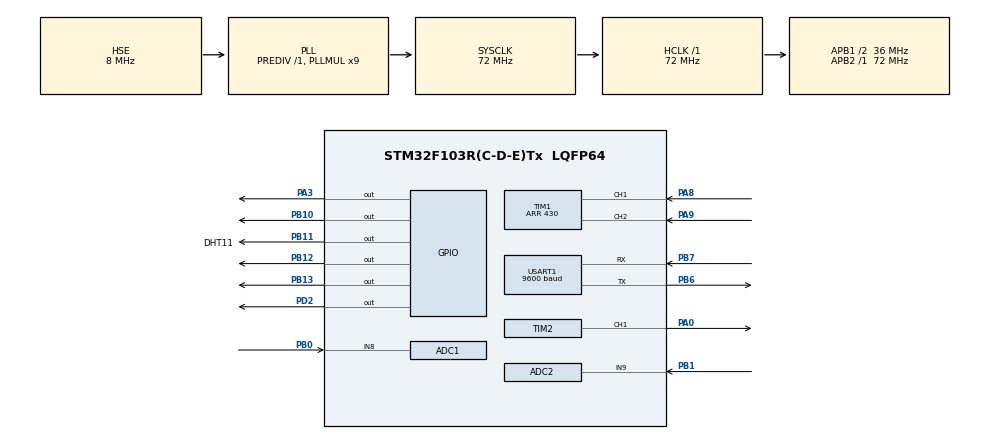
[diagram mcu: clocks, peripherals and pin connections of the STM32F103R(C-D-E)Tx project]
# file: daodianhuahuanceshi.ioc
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ADC1.Channel-18\#ChannelRegularConversion=ADC_CHANNEL_8
ADC1.ContinuousConvMode=DISABLE
ADC1.DataAlign=ADC_DATAALIGN_RIGHT
ADC1.DiscontinuousConvMode=DISABLE
ADC1.EnableAnalogWatchDog=false
ADC1.EnableRegularConversion=ENABLE
ADC1.ExternalTrigConv=ADC_SOFTWARE_START
ADC1.InjNumberOfConversion=0
ADC1.NbrOfConversion=1
ADC1.NbrOfConversionFlag=1
ADC1.Rank-18\#ChannelRegularConversion=1
ADC1.SamplingTime-18\#ChannelRegularConversion=ADC_SAMPLETIME_1CYCLE_5
ADC1.ScanConvMode=ADC_SCAN_DISABLE
ADC1.master=1
ADC2.Channel-2\#ChannelRegularConversion=ADC_CHANNEL_9
ADC2.NbrOfConversionFlag=1
ADC2.Rank-2\#ChannelRegularConversion=1
ADC2.SamplingTime-2\#ChannelRegularConversion=ADC_SAMPLETIME_1CYCLE_5
Mcu.Family=STM32F1
Mcu.Name=STM32F103R(C-D-E)Tx
Mcu.Package=LQFP64
NVIC.PriorityGroup=NVIC_PRIORITYGROUP_4
NVIC.TIM3_IRQn=true\:0\:0\:false\:false\:true\:true
PA0-WKUP.Signal=S_TIM2_CH1_ETR
PA13.Mode=Serial_Wire
PA13.Signal=SYS_JTMS-SWDIO
PA14.Mode=Serial_Wire
PA14.Signal=SYS_JTCK-SWCLK
PA3.GPIO_PuPd=GPIO_PULLUP
PA3.PinState=GPIO_PIN_SET
PA3.Signal=GPIO_Output
PA8.GPIO_PuPd=GPIO_PULLUP
PA8.Signal=S_TIM1_CH1
PA9.GPIO_PuPd=GPIO_PULLUP
PA9.Signal=S_TIM1_CH2
PB0.Signal=ADCx_IN8
PB1.Signal=ADCx_IN9
PB10.PinState=GPIO_PIN_RESET
PB10.Signal=GPIO_Output
PB11.GPIO_Label=DHT11
PB11.GPIO_Speed=GPIO_SPEED_FREQ_HIGH
PB11.PinState=GPIO_PIN_SET
PB11.Signal=GPIO_Output
PB12.Signal=GPIO_Output
PB13.Signal=GPIO_Output
PB6.Mode=Asynchronous
PB6.Signal=USART1_TX
PB7.Mode=Asynchronous
PB7.Signal=USART1_RX
PD0-OSC_IN.Mode=HSE-External-Oscillator
PD0-OSC_IN.Signal=RCC_OSC_IN
PD1-OSC_OUT.Mode=HSE-External-Oscillator
PD1-OSC_OUT.Signal=RCC_OSC_OUT
PD2.Signal=GPIO_Output
ProjectManager.HeapSize=0x200
ProjectManager.StackSize=0x400
ProjectManager.TargetToolchain=MDK-ARM V5
RCC.ADCPresc=RCC_ADCPCLK2_DIV6
RCC.AHBFreq_Value=72000000
RCC.APB1CLKDivider=RCC_HCLK_DIV2
RCC.APB1Freq_Value=36000000
RCC.APB1TimFreq_Value=72000000
RCC.APB2Freq_Value=72000000
RCC.APB2TimFreq_Value=72000000
RCC.HCLKFreq_Value=72000000
RCC.PLLMUL=RCC_PLL_MUL9
RCC.PLLSourceVirtual=RCC_PLLSOURCE_HSE
RCC.SYSCLKFreq_VALUE=72000000
RCC.SYSCLKSource=RCC_SYSCLKSOURCE_PLLCLK
RCC.USBFreq_Value=72000000
SH.ADCx_IN8.0=ADC1_IN8,IN8
SH.ADCx_IN9.0=ADC2_IN9,IN9
SH.S_TIM1_CH1.0=TIM1_CH1,Encoder_Interface
SH.S_TIM1_CH2.0=TIM1_CH2,Encoder_Interface
SH.S_TIM2_CH1_ETR.0=TIM2_CH1,PWM Generation1 CH1
TIM1.EncoderMode=TIM_ENCODERMODE_TI12
TIM1.IC1Prescaler=TIM_ICPSC_DIV1
TIM1.IC2Prescaler=TIM_ICPSC_DIV1
TIM1.Period=430
TIM2.Channel-PWM\ Generation1\ CH1=TIM_CHANNEL_1
TIM2.Period=9999
TIM2.Prescaler=143
TIM2.Pulse-PWM\ Generation1\ CH1=3000
TIM3.Period=999
TIM3.Prescaler=719
USART1.BaudRate=9600
USART1.VirtualMode=VM_ASYNC
VP_TIM2_VS_ClockSourceINT.Mode=Internal
VP_TIM3_VS_ClockSourceINT.Mode=Internal
board=custom

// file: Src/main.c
/**
  ******************************************************************************
  * @file           : main.c
  * @brief          : Main program body
  ******************************************************************************
  ** This notice applies to any and all portions of this file
  * that are not between comment pairs USER CODE BEGIN and
  * USER CODE END. Other portions of this file, whether
  * inserted by the user or by software development tools
  * are owned by their respective copyright owners.
  *
  * COPYRIGHT(c) 2019 STMicroelectronics
  *
  * Redistribution and use in source and binary forms, with or without modification,
  * are permitted provided that the following conditions are met:
  *   1. Redistributions of source code must retain the above copyright notice,
  *      this list of conditions and the following disclaimer.
  *   2. Redistributions in binary form must reproduce the above copyright notice,
  *      this list of conditions and the following disclaimer in the documentation
  *      and/or other materials provided with the distribution.
  *   3. Neither the name of STMicroelectronics nor the names of its contributors
  *      may be used to endorse or promote products derived from this software
  *      without specific prior written permission.
  *
  * THIS SOFTWARE IS PROVIDED BY THE COPYRIGHT HOLDERS AND CONTRIBUTORS "AS IS"
  * AND ANY EXPRESS OR IMPLIED WARRANTIES, INCLUDING, BUT NOT LIMITED TO, THE
  * IMPLIED WARRANTIES OF MERCHANTABILITY AND FITNESS FOR A PARTICULAR PURPOSE ARE
  * DISCLAIMED. IN NO EVENT SHALL THE COPYRIGHT HOLDER OR CONTRIBUTORS BE LIABLE
  * FOR ANY DIRECT, INDIRECT, INCIDENTAL, SPECIAL, EXEMPLARY, OR CONSEQUENTIAL
  * DAMAGES (INCLUDING, BUT NOT LIMITED TO, PROCUREMENT OF SUBSTITUTE GOODS OR
  * SERVICES; LOSS OF USE, DATA, OR PROFITS; OR BUSINESS INTERRUPTION) HOWEVER
  * CAUSED AND ON ANY THEORY OF LIABILITY, WHETHER IN CONTRACT, STRICT LIABILITY,
  * OR TORT (INCLUDING NEGLIGENCE OR OTHERWISE) ARISING IN ANY WAY OUT OF THE USE
  * OF THIS SOFTWARE, EVEN IF ADVISED OF THE POSSIBILITY OF SUCH DAMAGE.
  *
  ******************************************************************************
  */
#include "main.h"
#include "stm32f1xx_hal.h"

/* USER CODE BEGIN Includes */
#include "User.h"
/* USER CODE END Includes */

ADC_HandleTypeDef hadc1;
ADC_HandleTypeDef hadc2;

TIM_HandleTypeDef htim1;
TIM_HandleTypeDef htim2;
TIM_HandleTypeDef htim3;

UART_HandleTypeDef huart1;

/* USER CODE BEGIN PV */
/* Private variables ---------------------------------------------------------*/

/* USER CODE END PV */

void SystemClock_Config(void);
static void MX_GPIO_Init(void);
static void MX_USART1_UART_Init(void);
static void MX_ADC1_Init(void);
static void MX_ADC2_Init(void);
static void MX_TIM1_Init(void);
static void MX_TIM2_Init(void);
static void MX_TIM3_Init(void);

void HAL_TIM_MspPostInit(TIM_HandleTypeDef *htim);

/* USER CODE BEGIN PFP */
/* Private function prototypes -----------------------------------------------*/

/* USER CODE END PFP */

int main(void)
{

  /* MCU Configuration----------------------------------------------------------*/

  /* Reset of all peripherals, Initializes the Flash interface and the Systick. */
  HAL_Init();

  /* Configure the system clock */
  SystemClock_Config();

  /* Initialize all configured peripherals */
  MX_GPIO_Init();
  MX_USART1_UART_Init();
  MX_ADC1_Init();
  MX_ADC2_Init();
  MX_TIM1_Init();
  MX_TIM2_Init();
  MX_TIM3_Init();
  /* USER CODE BEGIN 2 */
    UserInitCallBack();
  /* USER CODE END 2 */

  /* Infinite loop */
  while (1)
  {

  /* USER CODE BEGIN 3 */
      UserServiceCallBack();

  }
  /* USER CODE END 3 */

}

void SystemClock_Config(void)
{

  RCC_OscInitTypeDef RCC_OscInitStruct;
  RCC_ClkInitTypeDef RCC_ClkInitStruct;
  RCC_PeriphCLKInitTypeDef PeriphClkInit;

    /**Initializes the CPU, AHB and APB busses clocks
    */
  RCC_OscInitStruct.OscillatorType = RCC_OSCILLATORTYPE_HSE;
  RCC_OscInitStruct.HSEState = RCC_HSE_ON;
  RCC_OscInitStruct.HSEPredivValue = RCC_HSE_PREDIV_DIV1;
  RCC_OscInitStruct.HSIState = RCC_HSI_ON;
  RCC_OscInitStruct.PLL.PLLState = RCC_PLL_ON;
  RCC_OscInitStruct.PLL.PLLSource = RCC_PLLSOURCE_HSE;
  RCC_OscInitStruct.PLL.PLLMUL = RCC_PLL_MUL9;
  if (HAL_RCC_OscConfig(&RCC_OscInitStruct) != HAL_OK)
  {
    _Error_Handler(__FILE__, __LINE__);
  }

    /**Initializes the CPU, AHB and APB busses clocks
    */
  RCC_ClkInitStruct.ClockType = RCC_CLOCKTYPE_HCLK|RCC_CLOCKTYPE_SYSCLK
                              |RCC_CLOCKTYPE_PCLK1|RCC_CLOCKTYPE_PCLK2;
  RCC_ClkInitStruct.SYSCLKSource = RCC_SYSCLKSOURCE_PLLCLK;
  RCC_ClkInitStruct.AHBCLKDivider = RCC_SYSCLK_DIV1;
  RCC_ClkInitStruct.APB1CLKDivider = RCC_HCLK_DIV2;
  RCC_ClkInitStruct.APB2CLKDivider = RCC_HCLK_DIV1;

  if (HAL_RCC_ClockConfig(&RCC_ClkInitStruct, FLASH_LATENCY_2) != HAL_OK)
  {
    _Error_Handler(__FILE__, __LINE__);
  }

  PeriphClkInit.PeriphClockSelection = RCC_PERIPHCLK_ADC;
  PeriphClkInit.AdcClockSelection = RCC_ADCPCLK2_DIV6;
  if (HAL_RCCEx_PeriphCLKConfig(&PeriphClkInit) != HAL_OK)
  {
    _Error_Handler(__FILE__, __LINE__);
  }

    /**Configure the Systick interrupt time
    */
  HAL_SYSTICK_Config(HAL_RCC_GetHCLKFreq()/1000);

    /**Configure the Systick
    */
  HAL_SYSTICK_CLKSourceConfig(SYSTICK_CLKSOURCE_HCLK);

  /* SysTick_IRQn interrupt configuration */
  HAL_NVIC_SetPriority(SysTick_IRQn, 0, 0);
}

/* ADC1 init function */
static void MX_ADC1_Init(void)
{

  ADC_ChannelConfTypeDef sConfig;

    /**Common config
    */
  hadc1.Instance = ADC1;
  hadc1.Init.ScanConvMode = ADC_SCAN_DISABLE;
  hadc1.Init.ContinuousConvMode = DISABLE;
  hadc1.Init.DiscontinuousConvMode = DISABLE;
  hadc1.Init.ExternalTrigConv = ADC_SOFTWARE_START;
  hadc1.Init.DataAlign = ADC_DATAALIGN_RIGHT;
  hadc1.Init.NbrOfConversion = 1;
  if (HAL_ADC_Init(&hadc1) != HAL_OK)
  {
    _Error_Handler(__FILE__, __LINE__);
  }

    /**Configure Regular Channel
    */
  sConfig.Channel = ADC_CHANNEL_8;
  sConfig.Rank = ADC_REGULAR_RANK_1;
  sConfig.SamplingTime = ADC_SAMPLETIME_1CYCLE_5;
  if (HAL_ADC_ConfigChannel(&hadc1, &sConfig) != HAL_OK)
  {
    _Error_Handler(__FILE__, __LINE__);
  }

}

/* ADC2 init function */
static void MX_ADC2_Init(void)
{

  ADC_ChannelConfTypeDef sConfig;

    /**Common config
    */
  hadc2.Instance = ADC2;
  hadc2.Init.ScanConvMode = ADC_SCAN_DISABLE;
  hadc2.Init.ContinuousConvMode = DISABLE;
  hadc2.Init.DiscontinuousConvMode = DISABLE;
  hadc2.Init.ExternalTrigConv = ADC_SOFTWARE_START;
  hadc2.Init.DataAlign = ADC_DATAALIGN_RIGHT;
  hadc2.Init.NbrOfConversion = 1;
  if (HAL_ADC_Init(&hadc2) != HAL_OK)
  {
    _Error_Handler(__FILE__, __LINE__);
  }

    /**Configure Regular Channel
    */
  sConfig.Channel = ADC_CHANNEL_9;
  sConfig.Rank = ADC_REGULAR_RANK_1;
  sConfig.SamplingTime = ADC_SAMPLETIME_1CYCLE_5;
  if (HAL_ADC_ConfigChannel(&hadc2, &sConfig) != HAL_OK)
  {
    _Error_Handler(__FILE__, __LINE__);
  }

}

/* TIM1 init function */
static void MX_TIM1_Init(void)
{

  TIM_Encoder_InitTypeDef sConfig;
  TIM_MasterConfigTypeDef sMasterConfig;

  htim1.Instance = TIM1;
  htim1.Init.Prescaler = 0;
  htim1.Init.CounterMode = TIM_COUNTERMODE_UP;
  htim1.Init.Period = 430;
  htim1.Init.ClockDivision = TIM_CLOCKDIVISION_DIV1;
  htim1.Init.RepetitionCounter = 0;
  htim1.Init.AutoReloadPreload = TIM_AUTORELOAD_PRELOAD_DISABLE;
  sConfig.EncoderMode = TIM_ENCODERMODE_TI12;
  sConfig.IC1Polarity = TIM_ICPOLARITY_RISING;
  sConfig.IC1Selection = TIM_ICSELECTION_DIRECTTI;
  sConfig.IC1Prescaler = TIM_ICPSC_DIV1;
  sConfig.IC1Filter = 0;
  sConfig.IC2Polarity = TIM_ICPOLARITY_RISING;
  sConfig.IC2Selection = TIM_ICSELECTION_DIRECTTI;
  sConfig.IC2Prescaler = TIM_ICPSC_DIV1;
  sConfig.IC2Filter = 0;
  if (HAL_TIM_Encoder_Init(&htim1, &sConfig) != HAL_OK)
  {
    _Error_Handler(__FILE__, __LINE__);
  }

  sMasterConfig.MasterOutputTrigger = TIM_TRGO_RESET;
  sMasterConfig.MasterSlaveMode = TIM_MASTERSLAVEMODE_DISABLE;
  if (HAL_TIMEx_MasterConfigSynchronization(&htim1, &sMasterConfig) != HAL_OK)
  {
    _Error_Handler(__FILE__, __LINE__);
  }

}

/* TIM2 init function */
static void MX_TIM2_Init(void)
{

  TIM_ClockConfigTypeDef sClockSourceConfig;
  TIM_MasterConfigTypeDef sMasterConfig;
  TIM_OC_InitTypeDef sConfigOC;

  htim2.Instance = TIM2;
  htim2.Init.Prescaler = 143;
  htim2.Init.CounterMode = TIM_COUNTERMODE_UP;
  htim2.Init.Period = 9999;
  htim2.Init.ClockDivision = TIM_CLOCKDIVISION_DIV1;
  htim2.Init.AutoReloadPreload = TIM_AUTORELOAD_PRELOAD_DISABLE;
  if (HAL_TIM_Base_Init(&htim2) != HAL_OK)
  {
    _Error_Handler(__FILE__, __LINE__);
  }

  sClockSourceConfig.ClockSource = TIM_CLOCKSOURCE_INTERNAL;
  if (HAL_TIM_ConfigClockSource(&htim2, &sClockSourceConfig) != HAL_OK)
  {
    _Error_Handler(__FILE__, __LINE__);
  }

  if (HAL_TIM_PWM_Init(&htim2) != HAL_OK)
  {
    _Error_Handler(__FILE__, __LINE__);
  }

  sMasterConfig.MasterOutputTrigger = TIM_TRGO_RESET;
  sMasterConfig.MasterSlaveMode = TIM_MASTERSLAVEMODE_DISABLE;
  if (HAL_TIMEx_MasterConfigSynchronization(&htim2, &sMasterConfig) != HAL_OK)
  {
    _Error_Handler(__FILE__, __LINE__);
  }

  sConfigOC.OCMode = TIM_OCMODE_PWM1;
  sConfigOC.Pulse = 0;
  sConfigOC.OCPolarity = TIM_OCPOLARITY_HIGH;
  sConfigOC.OCFastMode = TIM_OCFAST_DISABLE;
  if (HAL_TIM_PWM_ConfigChannel(&htim2, &sConfigOC, TIM_CHANNEL_1) != HAL_OK)
  {
    _Error_Handler(__FILE__, __LINE__);
  }

  HAL_TIM_MspPostInit(&htim2);

}

/* TIM3 init function */
static void MX_TIM3_Init(void)
{

  TIM_ClockConfigTypeDef sClockSourceConfig;
  TIM_MasterConfigTypeDef sMasterConfig;

  htim3.Instance = TIM3;
  htim3.Init.Prescaler = 719;
  htim3.Init.CounterMode = TIM_COUNTERMODE_UP;
  htim3.Init.Period = 999;
  htim3.Init.ClockDivision = TIM_CLOCKDIVISION_DIV1;
  htim3.Init.AutoReloadPreload = TIM_AUTORELOAD_PRELOAD_DISABLE;
  if (HAL_TIM_Base_Init(&htim3) != HAL_OK)
  {
    _Error_Handler(__FILE__, __LINE__);
  }

  sClockSourceConfig.ClockSource = TIM_CLOCKSOURCE_INTERNAL;
  if (HAL_TIM_ConfigClockSource(&htim3, &sClockSourceConfig) != HAL_OK)
  {
    _Error_Handler(__FILE__, __LINE__);
  }

  sMasterConfig.MasterOutputTrigger = TIM_TRGO_RESET;
  sMasterConfig.MasterSlaveMode = TIM_MASTERSLAVEMODE_DISABLE;
  if (HAL_TIMEx_MasterConfigSynchronization(&htim3, &sMasterConfig) != HAL_OK)
  {
    _Error_Handler(__FILE__, __LINE__);
  }

}

/* USART1 init function */
static void MX_USART1_UART_Init(void)
{

  huart1.Instance = USART1;
  huart1.Init.BaudRate = 9600;
  huart1.Init.WordLength = UART_WORDLENGTH_8B;
  huart1.Init.StopBits = UART_STOPBITS_1;
  huart1.Init.Parity = UART_PARITY_NONE;
  huart1.Init.Mode = UART_MODE_TX_RX;
  huart1.Init.HwFlowCtl = UART_HWCONTROL_NONE;
  huart1.Init.OverSampling = UART_OVERSAMPLING_16;
  if (HAL_UART_Init(&huart1) != HAL_OK)
  {
    _Error_Handler(__FILE__, __LINE__);
  }

}

/** Configure pins as
        * Analog
        * Input
        * Output
        * EVENT_OUT
        * EXTI
*/
static void MX_GPIO_Init(void)
{

  GPIO_InitTypeDef GPIO_InitStruct;

  /* GPIO Ports Clock Enable */
  __HAL_RCC_GPIOD_CLK_ENABLE();
  __HAL_RCC_GPIOA_CLK_ENABLE();
  __HAL_RCC_GPIOB_CLK_ENABLE();

  /*Configure GPIO pin Output Level */
  HAL_GPIO_WritePin(GPIOA, GPIO_PIN_3, GPIO_PIN_SET);

  /*Configure GPIO pin Output Level */
  HAL_GPIO_WritePin(GPIOB, GPIO_PIN_10|GPIO_PIN_12|GPIO_PIN_13, GPIO_PIN_RESET);

  /*Configure GPIO pin Output Level */
  HAL_GPIO_WritePin(DHT11_GPIO_Port, DHT11_Pin, GPIO_PIN_SET);

  /*Configure GPIO pin Output Level */
  HAL_GPIO_WritePin(GPIOD, GPIO_PIN_2, GPIO_PIN_RESET);

  /*Configure GPIO pin : PA3 */
  GPIO_InitStruct.Pin = GPIO_PIN_3;
  GPIO_InitStruct.Mode = GPIO_MODE_OUTPUT_PP;
  GPIO_InitStruct.Pull = GPIO_PULLUP;
  GPIO_InitStruct.Speed = GPIO_SPEED_FREQ_LOW;
  HAL_GPIO_Init(GPIOA, &GPIO_InitStruct);

  /*Configure GPIO pins : PB10 PB12 PB13 */
  GPIO_InitStruct.Pin = GPIO_PIN_10|GPIO_PIN_12|GPIO_PIN_13;
  GPIO_InitStruct.Mode = GPIO_MODE_OUTPUT_PP;
  GPIO_InitStruct.Pull = GPIO_NOPULL;
  GPIO_InitStruct.Speed = GPIO_SPEED_FREQ_LOW;
  HAL_GPIO_Init(GPIOB, &GPIO_InitStruct);

  /*Configure GPIO pin : DHT11_Pin */
  GPIO_InitStruct.Pin = DHT11_Pin;
  GPIO_InitStruct.Mode = GPIO_MODE_OUTPUT_PP;
  GPIO_InitStruct.Pull = GPIO_NOPULL;
  GPIO_InitStruct.Speed = GPIO_SPEED_FREQ_HIGH;
  HAL_GPIO_Init(DHT11_GPIO_Port, &GPIO_InitStruct);

  /*Configure GPIO pin : PD2 */
  GPIO_InitStruct.Pin = GPIO_PIN_2;
  GPIO_InitStruct.Mode = GPIO_MODE_OUTPUT_PP;
  GPIO_InitStruct.Pull = GPIO_NOPULL;
  GPIO_InitStruct.Speed = GPIO_SPEED_FREQ_LOW;
  HAL_GPIO_Init(GPIOD, &GPIO_InitStruct);

}

void _Error_Handler(char *file, int line)
{
  while(1)
  {
  }
}

/************************ (C) COPYRIGHT STMicroelectronics *****END OF FILE****/
